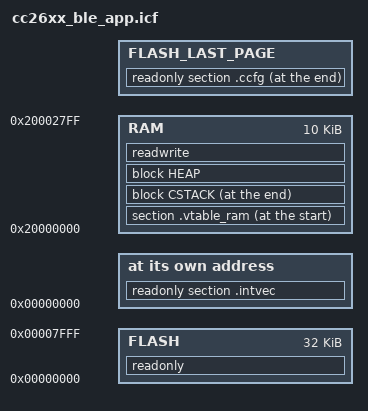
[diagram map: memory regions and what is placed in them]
////////////////////////////////////////////////////////////////////////////////
// Memory Sizes
////////////////////////////////////////////////////////////////////////////////
  define symbol RAM_SIZE            = 0x00005000;  // 20K
  define symbol FLASH_SIZE          = 0x00020000;  // 128K
  define symbol ROM_SIZE            = 0x0001C000;  // 115K

////////////////////////////////////////////////////////////////////////////////
// Memory Definitions
////////////////////////////////////////////////////////////////////////////////

////////////////////////////////////////////////////////////////////////////////
// RAM
//
define symbol RAM_START           = 0x20000000;

if ( isdefinedsymbol(ICALL_RAM0_ADDR) )
{
  define symbol RAM_END           = (ICALL_RAM0_ADDR-1);
}
else // default
{
  define symbol RAM_END           = 0x200027FF;
}

////////////////////////////////////////////////////////////////////////////////
// Flash
//
define symbol FLASH_START           = 0x00000000;

if ( isdefinedsymbol(ICALL_STACK0_ADDR) )
{
  define symbol FLASH_END           = (ICALL_STACK0_ADDR-1);
}
else // default
{
  define symbol FLASH_END           = 0x00007FFF;
}

////////////////////////////////////////////////////////////////////////////////
// Stack
//

define symbol STACK_SIZE           = 0x400;
define symbol STACK_START          = RAM_END + 1;
define symbol STACK_END            = STACK_START - STACK_SIZE;
define block CSTACK with alignment = 8, size = STACK_SIZE { section .stack };
//
define symbol STACK_TOP            = RAM_END + 1;
export symbol STACK_TOP;

////////////////////////////////////////////////////////////////////////////////
// Heap
//

define symbol HEAP_SIZE            = 0x1000;
define block  HEAP with alignment  = 8, size = HEAP_SIZE { };

////////////////////////////////////////////////////////////////////////////////
// Flash Interrupt Vector Table
//

define symbol INTVEC_NUM_ENTRIES   = 50 + 1; // first entry is stack location
define symbol INTVEC_SIZE          = INTVEC_NUM_ENTRIES + 4;

////////////////////////////////////////////////////////////////////////////////
// Memory Regions
////////////////////////////////////////////////////////////////////////////////

define memory mem with size = 4G;

define region RAM             = mem:[from RAM_START   to RAM_END];
define region FLASH_LAST_PAGE = mem:[from(FLASH_SIZE) - 0x1000 to FLASH_SIZE-1];
define region FLASH           = mem:[from FLASH_START to FLASH_END];

////////////////////////////////////////////////////////////////////////////////
// Memory Placement
////////////////////////////////////////////////////////////////////////////////

// CCFG
place at end of FLASH_LAST_PAGE { readonly section .ccfg };
keep { section .ccfg };

// Interrupt Vector Table
place at address mem:FLASH_START { readonly section .intvec };
keep                             { readonly section .intvec };

// RAM Vector Table
place at start of RAM { section .vtable_ram };

// Stack
place at end of RAM { block CSTACK };

// Heap
place in RAM { block HEAP };

place in FLASH { readonly };
place in RAM   { readwrite };

////////////////////////////////////////////////////////////////////////////////
// Initialization
////////////////////////////////////////////////////////////////////////////////

initialize by copy { readwrite };

do not initialize
{
  section .noinit,
  section .stack,
};

////////////////////////////////////////////////////////////////////////////////
// The USE_TIRTOS_ROM symbol is defined internally in the build flow (using
// --config_def USE_TIRTOS_ROM=1) for TI-RTOS applications whose appBLE.cfg file
// specifies to use the ROM.
//
if (isdefinedsymbol(USE_TIRTOS_ROM)) {
     include "TIRTOS_ROM.icf";
}
